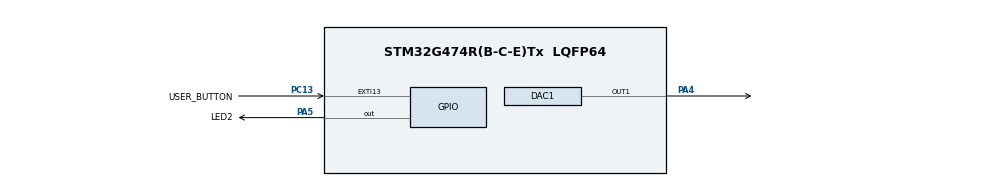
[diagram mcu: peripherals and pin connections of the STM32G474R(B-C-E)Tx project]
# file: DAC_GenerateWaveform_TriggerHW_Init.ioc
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DAC1.DAC_Trigger2_OUT1-DAC_OUT1=DAC_TRIGGER_NONE
DAC1.DAC_Trigger_OUT1-DAC_OUT1=DAC_TRIGGER_T6_TRGO
Dma.DAC1_CH1.0.Direction=DMA_MEMORY_TO_PERIPH
Dma.DAC1_CH1.0.EventEnable=DISABLE
Dma.DAC1_CH1.0.Instance=DMA1_Channel3
Dma.DAC1_CH1.0.MemDataAlignment=DMA_MDATAALIGN_HALFWORD
Dma.DAC1_CH1.0.MemInc=DMA_MINC_ENABLE
Dma.DAC1_CH1.0.Mode=DMA_CIRCULAR
Dma.DAC1_CH1.0.PeriphDataAlignment=DMA_PDATAALIGN_WORD
Dma.DAC1_CH1.0.PeriphInc=DMA_PINC_DISABLE
Dma.DAC1_CH1.0.Polarity=HAL_DMAMUX_REQUEST_GEN_RISING
Dma.DAC1_CH1.0.Priority=DMA_PRIORITY_HIGH
Dma.DAC1_CH1.0.RequestNumber=1
Dma.DAC1_CH1.0.SignalID=HAL_DMAMUX1_REQUEST_GEN_EXTI13
Dma.DAC1_CH1.0.SyncEnable=DISABLE
Dma.DAC1_CH1.0.SyncPolarity=HAL_DMAMUX_SYNC_NO_EVENT
Dma.DAC1_CH1.0.SyncRequestNumber=1
Dma.DAC1_CH1.0.SyncSignalID=HAL_DMAMUX1_SYNC_EXTI13
Dma.Request0=DAC1_CH1
Mcu.Family=STM32G4
Mcu.Name=STM32G474R(B-C-E)Tx
Mcu.Package=LQFP64
NVIC.DMA1_Channel3_IRQn=true\:0\:0\:false\:false\:true\:false\:true
NVIC.EXTI15_10_IRQn=true\:0\:0\:false\:false\:true\:true\:true
NVIC.PriorityGroup=NVIC_PRIORITYGROUP_4
NVIC.TIM6_DAC_IRQn=true\:0\:0\:false\:false\:true\:true\:true
PA4.Signal=COMP_DAC11_group
PA5.GPIO_Label=LED2
PA5.Signal=GPIO_Output
PC13.GPIO_Label=USER_BUTTON
PC13.GPIO_ModeDefaultEXTI=GPIO_MODE_IT_FALLING
PC13.Signal=GPXTI13
ProjectManager.HeapSize=0x200
ProjectManager.StackSize=0x400
ProjectManager.TargetToolchain=EWARM V8
RCC.ADC12Freq_Value=150000000
RCC.ADC345Freq_Value=150000000
RCC.AHBFreq_Value=150000000
RCC.APB1Freq_Value=150000000
RCC.APB1TimFreq_Value=150000000
RCC.APB2Freq_Value=150000000
RCC.APB2TimFreq_Value=150000000
RCC.CortexFreq_Value=150000000
RCC.EXTERNAL_CLOCK_VALUE=12288000
RCC.HCLKFreq_Value=150000000
RCC.HSE_VALUE=24000000
RCC.HSI48_VALUE=16000000
RCC.HSI_VALUE=16000000
RCC.LSE_VALUE=32768
RCC.PLLM=RCC_PLLM_DIV4
RCC.PLLN=75
RCC.SYSCLKFreq_VALUE=150000000
RCC.SYSCLKSource=RCC_SYSCLKSOURCE_PLLCLK
RCC.USBFreq_Value=150000000
RCC.VCOOutputFreq_Value=300000000
SH.COMP_DAC11_group.0=DAC1_OUT1,DAC_OUT1
TIM6.AutoReloadPreload=TIM_AUTORELOAD_PRELOAD_DISABLE
TIM6.CounterMode=TIM_COUNTERMODE_UP
TIM6.Period=(timer_reload - 1)
TIM6.Prescaler=(timer_prescaler - 1)
TIM6.TIM_MasterOutputTrigger=TIM_TRGO_UPDATE
VP_SYS_VS_DBSignals.Mode=DisableDeadBatterySignals
VP_TIM6_VS_ClockSourceINT.Mode=Enable_Timer
board=NUCLEO-G474RE

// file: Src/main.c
/* USER CODE BEGIN Header */
/**
  ******************************************************************************
  * @file    Examples_LL/DAC/DAC_GenerateWaveform_TriggerHW_Init/Src/main.c
  * @author  MCD Application Team
  * @brief   This example describes how to use the DAC peripheral to generate
  *          a voltage waveform from digital data stream transferred by DMA.
  *          This example is based on the STM32G4xx DAC LL API;
  *          Peripheral initialization done using LL initialization function.
  ******************************************************************************
  * @attention
  *
  * <h2><center>&copy; Copyright (c) 2019 STMicroelectronics.
  * All rights reserved.</center></h2>
  *
  * This software component is licensed by ST under BSD 3-Clause license,
  * the "License"; You may not use this file except in compliance with the
  * License. You may obtain a copy of the License at:
  *                        opensource.org/licenses/BSD-3-Clause
  *
  ******************************************************************************
  */
/* USER CODE END Header */
#include "main.h"

/* USER CODE BEGIN PD */

/* Definitions of environment analog values */
  /* Value of analog reference voltage (Vref+), connected to analog voltage   */
  /* supply Vdda (unit: mV).                                                  */
  #define VDDA_APPLI                       ((uint32_t)3300)

/* Definitions of data related to this example */
/* Full-scale digital value with a resolution of 12 bits (voltage range     */
/* determined by analog voltage references Vref+ and Vref-,                 */
/* refer to reference manual).                                              */
#define DIGITAL_SCALE_12BITS             (__LL_DAC_DIGITAL_SCALE(LL_DAC_RESOLUTION_12B))

/* Definitions of waveform generation values */
/* Waveform generation: parameters of waveform */
/* Waveform amplitude (unit: mV) */
#define WAVEFORM_AMPLITUDE          (VDDA_APPLI)
/* Waveform amplitude (unit: Hz) */
#define WAVEFORM_FREQUENCY          ((uint32_t)1000)
/* Size of array containing DAC waveform samples */
#define WAVEFORM_SAMPLES_SIZE       (sizeof (WaveformSine_12bits_32samples) / sizeof (uint16_t))

/* Waveform generation: parameters of timer (used as DAC trigger) */
/* Timer frequency (unit: Hz). With a timer 16 bits and time base           */
/* freq min 1Hz, range is min=1Hz, max=32kHz.                               */
#define WAVEFORM_TIMER_FREQUENCY                (WAVEFORM_FREQUENCY * WAVEFORM_SAMPLES_SIZE)
/* Timer minimum frequency (unit: Hz), used to calculate frequency range.   */
/* With a timer 16 bits, maximum frequency will be 32000 times this value.  */
#define WAVEFORM_TIMER_FREQUENCY_RANGE_MIN      ((uint32_t)    1)
/* Timer prescaler maximum value (0xFFFF for a timer 16 bits) */
#define WAVEFORM_TIMER_PRESCALER_MAX_VALUE      ((uint32_t)0xFFFF-1)

/**
  * @brief Toggle periods for various blinking modes
  */
#define LED_BLINK_FAST  200
#define LED_BLINK_SLOW  500
#define LED_BLINK_ERROR 1000

/* USER CODE END PD */

/* USER CODE BEGIN PM */

/**
  * @brief  Computation of a data from maximum value on digital scale 12 bits
  *         (corresponding to voltage Vdda)
  *         to a value on the new scale
  *         (corresponding to voltage defined by WAVEFORM_AMPLITUDE).
  * @param  __DATA_12BITS__: Digital value on scale 12 bits
  * @retval None
  */
#define __WAVEFORM_AMPLITUDE_SCALING(__DATA_12BITS__)                                     \
  (__DATA_12BITS__                                                                        \
   * __LL_DAC_CALC_VOLTAGE_TO_DATA(VDDA_APPLI, WAVEFORM_AMPLITUDE, LL_DAC_RESOLUTION_12B) \
   / __LL_DAC_DIGITAL_SCALE(LL_DAC_RESOLUTION_12B)                                        \
  )

/* USER CODE END PM */

/* USER CODE BEGIN PV */

__IO uint8_t ubButtonPress = 0;

uint32_t timer_prescaler = 0;                   /* Time base prescaler to have timebase aligned on minimum frequency possible */
uint32_t timer_reload = 0;                      /* Timer reload value in function of timer prescaler to achieve time base period */

const uint16_t WaveformSine_12bits_32samples[] =
{
__WAVEFORM_AMPLITUDE_SCALING(2048),
__WAVEFORM_AMPLITUDE_SCALING(2447),
__WAVEFORM_AMPLITUDE_SCALING(2831),
__WAVEFORM_AMPLITUDE_SCALING(3185),
__WAVEFORM_AMPLITUDE_SCALING(3495),
__WAVEFORM_AMPLITUDE_SCALING(3750),
__WAVEFORM_AMPLITUDE_SCALING(3939),
__WAVEFORM_AMPLITUDE_SCALING(4056),
__WAVEFORM_AMPLITUDE_SCALING(4095),
__WAVEFORM_AMPLITUDE_SCALING(4056),
__WAVEFORM_AMPLITUDE_SCALING(3939),
__WAVEFORM_AMPLITUDE_SCALING(3750),
__WAVEFORM_AMPLITUDE_SCALING(3495),
__WAVEFORM_AMPLITUDE_SCALING(3185),
__WAVEFORM_AMPLITUDE_SCALING(2831),
__WAVEFORM_AMPLITUDE_SCALING(2447),
__WAVEFORM_AMPLITUDE_SCALING(2048),
__WAVEFORM_AMPLITUDE_SCALING(1649),
__WAVEFORM_AMPLITUDE_SCALING(1265),
__WAVEFORM_AMPLITUDE_SCALING(911),
__WAVEFORM_AMPLITUDE_SCALING(601),
__WAVEFORM_AMPLITUDE_SCALING(346),
__WAVEFORM_AMPLITUDE_SCALING(157),
__WAVEFORM_AMPLITUDE_SCALING(40),
__WAVEFORM_AMPLITUDE_SCALING(0),
__WAVEFORM_AMPLITUDE_SCALING(40),
__WAVEFORM_AMPLITUDE_SCALING(157),
__WAVEFORM_AMPLITUDE_SCALING(346),
__WAVEFORM_AMPLITUDE_SCALING(601),
__WAVEFORM_AMPLITUDE_SCALING(911),
__WAVEFORM_AMPLITUDE_SCALING(1265),
__WAVEFORM_AMPLITUDE_SCALING(1649)
};

/* USER CODE END PV */

void SystemClock_Config(void);
static void MX_GPIO_Init(void);
static void MX_DMA_Init(void);
static void MX_DAC1_Init(void);
static void MX_TIM6_Init(void);
/* USER CODE BEGIN PFP */

void Activate_DAC(void);
void LED_On(void);
void LED_Off(void);
void LED_Blinking(uint32_t Period);
void WaitForUserButtonPress(void);
void TIM_PrescalerReloadCalculation(void);

/* USER CODE END PFP */

int main(void)
{

  /* MCU Configuration--------------------------------------------------------*/

  /* Reset of all peripherals, Initializes the Flash interface and the Systick. */

  LL_APB2_GRP1_EnableClock(LL_APB2_GRP1_PERIPH_SYSCFG);
  LL_APB1_GRP1_EnableClock(LL_APB1_GRP1_PERIPH_PWR);

  NVIC_SetPriorityGrouping(NVIC_PRIORITYGROUP_4);

  /* System interrupt init*/

  /** Disable the internal Pull-Up in Dead Battery pins of UCPD peripheral
  */
  LL_PWR_DisableUCPDDeadBattery();

  /* Configure the system clock */
  SystemClock_Config();

  /* USER CODE BEGIN SysInit */
  TIM_PrescalerReloadCalculation();

  /* USER CODE END SysInit */

  /* Initialize all configured peripherals */
  MX_GPIO_Init();
  MX_DMA_Init();
  MX_DAC1_Init();
  MX_TIM6_Init();
  /* USER CODE BEGIN 2 */

  /* Wait for User push-button press */
  WaitForUserButtonPress();

  /* Turn-off LED4 */
  LED_Off();

  /* Set DMA transfer addresses of source and destination */
  LL_DMA_ConfigAddresses(DMA1,
                         LL_DMA_CHANNEL_3,
                         (uint32_t)&WaveformSine_12bits_32samples,
                         LL_DAC_DMA_GetRegAddr(DAC1, LL_DAC_CHANNEL_1, LL_DAC_DMA_REG_DATA_12BITS_RIGHT_ALIGNED),
                         LL_DMA_DIRECTION_MEMORY_TO_PERIPH);

  /* Set DMA transfer size */
  LL_DMA_SetDataLength(DMA1,
                       LL_DMA_CHANNEL_3,
                       WAVEFORM_SAMPLES_SIZE);

  /* Enable DMA transfer interruption: transfer error */
  LL_DMA_EnableIT_TE(DMA1,
                     LL_DMA_CHANNEL_3);

  /* Note: In this example, the only DMA interruption activated is            */
  /*       transfer error.                                                     */
  /*       If needed, DMA interruptions of half of transfer                   */
  /*       and transfer complete can be activated.                            */
  /*       Refer to DMA examples.                                             */

  /* Activation of DMA */
  /* Enable the DMA transfer */
  LL_DMA_EnableChannel(DMA1,
                       LL_DMA_CHANNEL_3);

  /* Set DAC mode sample-and-hold timings */
  // LL_DAC_SetSampleAndHoldSampleTime (DAC1, LL_DAC_CHANNEL_1, 0x3FF);
  // LL_DAC_SetSampleAndHoldHoldTime   (DAC1, LL_DAC_CHANNEL_1, 0x3FF);
  // LL_DAC_SetSampleAndHoldRefreshTime(DAC1, LL_DAC_CHANNEL_1, 0xFF);

  /* Set the mode for the selected DAC channel */
  // LL_DAC_SetMode(DAC1, LL_DAC_CHANNEL_1, LL_DAC_MODE_NORMAL_OPERATION);

  /* Enable DAC channel DMA request */
  LL_DAC_EnableDMAReq(DAC1, LL_DAC_CHANNEL_1);

  /* Enable interruption DAC channel1 under-run */
  LL_DAC_EnableIT_DMAUDR1(DAC1);

  /* Activation of Timer */
  /* Enable counter */
  LL_TIM_EnableCounter(TIM6);

  /* Activation of DAC channel */
  Activate_DAC();

  /* Turn-on LED4 */
  LED_On();

  /* USER CODE END 2 */

  /* Infinite loop */
  while (1)
  {

  }
}

void SystemClock_Config(void)
{
  LL_FLASH_SetLatency(LL_FLASH_LATENCY_4);
  while(LL_FLASH_GetLatency() != LL_FLASH_LATENCY_4)
  {
  }
  LL_PWR_SetRegulVoltageScaling(LL_PWR_REGU_VOLTAGE_SCALE1);
  LL_RCC_HSI_Enable();
   /* Wait till HSI is ready */
  while(LL_RCC_HSI_IsReady() != 1)
  {
  }

  LL_RCC_HSI_SetCalibTrimming(64);
  LL_RCC_PLL_ConfigDomain_SYS(LL_RCC_PLLSOURCE_HSI, LL_RCC_PLLM_DIV_4, 75, LL_RCC_PLLR_DIV_2);
  LL_RCC_PLL_EnableDomain_SYS();
  LL_RCC_PLL_Enable();
   /* Wait till PLL is ready */
  while(LL_RCC_PLL_IsReady() != 1)
  {
  }

  LL_RCC_SetSysClkSource(LL_RCC_SYS_CLKSOURCE_PLL);
  LL_RCC_SetAHBPrescaler(LL_RCC_SYSCLK_DIV_2);
   /* Wait till System clock is ready */
  while(LL_RCC_GetSysClkSource() != LL_RCC_SYS_CLKSOURCE_STATUS_PLL)
  {
  }

  /* Insure 1�s transition state at intermediate medium speed clock based on DWT */
  CoreDebug->DEMCR |= CoreDebug_DEMCR_TRCENA_Msk;
  DWT->CTRL |= DWT_CTRL_CYCCNTENA_Msk;
  DWT->CYCCNT = 0;
  while(DWT->CYCCNT < 100);
  /* Set AHB prescaler*/
  LL_RCC_SetAHBPrescaler(LL_RCC_SYSCLK_DIV_1);
  LL_RCC_SetAPB1Prescaler(LL_RCC_APB1_DIV_1);
  LL_RCC_SetAPB2Prescaler(LL_RCC_APB2_DIV_1);

  LL_Init1msTick(150000000);

  LL_SetSystemCoreClock(150000000);
}

static void MX_DAC1_Init(void)
{

  LL_DAC_InitTypeDef DAC_InitStruct = {0};

  LL_GPIO_InitTypeDef GPIO_InitStruct = {0};

  /* Peripheral clock enable */
  LL_AHB2_GRP1_EnableClock(LL_AHB2_GRP1_PERIPH_DAC1);

  LL_AHB2_GRP1_EnableClock(LL_AHB2_GRP1_PERIPH_GPIOA);
  /**DAC1 GPIO Configuration
  PA4   ------> DAC1_OUT1
  */
  GPIO_InitStruct.Pin = LL_GPIO_PIN_4;
  GPIO_InitStruct.Mode = LL_GPIO_MODE_ANALOG;
  GPIO_InitStruct.Pull = LL_GPIO_PULL_NO;
  LL_GPIO_Init(GPIOA, &GPIO_InitStruct);

  /* DAC1 DMA Init */

  /* DAC1_CH1 Init */
  LL_DMA_SetPeriphRequest(DMA1, LL_DMA_CHANNEL_3, LL_DMAMUX_REQ_DAC1_CH1);

  LL_DMA_SetDataTransferDirection(DMA1, LL_DMA_CHANNEL_3, LL_DMA_DIRECTION_MEMORY_TO_PERIPH);

  LL_DMA_SetChannelPriorityLevel(DMA1, LL_DMA_CHANNEL_3, LL_DMA_PRIORITY_HIGH);

  LL_DMA_SetMode(DMA1, LL_DMA_CHANNEL_3, LL_DMA_MODE_CIRCULAR);

  LL_DMA_SetPeriphIncMode(DMA1, LL_DMA_CHANNEL_3, LL_DMA_PERIPH_NOINCREMENT);

  LL_DMA_SetMemoryIncMode(DMA1, LL_DMA_CHANNEL_3, LL_DMA_MEMORY_INCREMENT);

  LL_DMA_SetPeriphSize(DMA1, LL_DMA_CHANNEL_3, LL_DMA_PDATAALIGN_WORD);

  LL_DMA_SetMemorySize(DMA1, LL_DMA_CHANNEL_3, LL_DMA_MDATAALIGN_HALFWORD);

  /* DAC1 interrupt Init */
  NVIC_SetPriority(TIM6_DAC_IRQn, NVIC_EncodePriority(NVIC_GetPriorityGrouping(),0, 0));
  NVIC_EnableIRQ(TIM6_DAC_IRQn);

  /** DAC channel OUT1 config
  */
  LL_DAC_SetSignedFormat(DAC1, LL_DAC_CHANNEL_1, LL_DAC_SIGNED_FORMAT_DISABLE);
  DAC_InitStruct.TriggerSource = LL_DAC_TRIG_EXT_TIM6_TRGO;
  DAC_InitStruct.TriggerSource2 = LL_DAC_TRIG_SOFTWARE;
  DAC_InitStruct.WaveAutoGeneration = LL_DAC_WAVE_AUTO_GENERATION_NONE;
  DAC_InitStruct.OutputBuffer = LL_DAC_OUTPUT_BUFFER_ENABLE;
  DAC_InitStruct.OutputConnection = LL_DAC_OUTPUT_CONNECT_GPIO;
  DAC_InitStruct.OutputMode = LL_DAC_OUTPUT_MODE_NORMAL;
  LL_DAC_Init(DAC1, LL_DAC_CHANNEL_1, &DAC_InitStruct);
  LL_DAC_EnableTrigger(DAC1, LL_DAC_CHANNEL_1);
  LL_DAC_DisableDMADoubleDataMode(DAC1, LL_DAC_CHANNEL_1);

}

static void MX_TIM6_Init(void)
{

  LL_TIM_InitTypeDef TIM_InitStruct = {0};

  /* Peripheral clock enable */
  LL_APB1_GRP1_EnableClock(LL_APB1_GRP1_PERIPH_TIM6);

  /* TIM6 interrupt Init */
  NVIC_SetPriority(TIM6_DAC_IRQn, NVIC_EncodePriority(NVIC_GetPriorityGrouping(),0, 0));
  NVIC_EnableIRQ(TIM6_DAC_IRQn);

  TIM_InitStruct.Prescaler = (timer_prescaler - 1);
  TIM_InitStruct.CounterMode = LL_TIM_COUNTERMODE_UP;
  TIM_InitStruct.Autoreload = (timer_reload - 1);
  LL_TIM_Init(TIM6, &TIM_InitStruct);
  LL_TIM_DisableARRPreload(TIM6);
  LL_TIM_SetTriggerOutput(TIM6, LL_TIM_TRGO_UPDATE);
  LL_TIM_DisableMasterSlaveMode(TIM6);

}

static void MX_DMA_Init(void)
{

  /* Init with LL driver */
  /* DMA controller clock enable */
  LL_AHB1_GRP1_EnableClock(LL_AHB1_GRP1_PERIPH_DMAMUX1);
  LL_AHB1_GRP1_EnableClock(LL_AHB1_GRP1_PERIPH_DMA1);

  /* DMA interrupt init */
  /* DMA1_Channel3_IRQn interrupt configuration */
  NVIC_SetPriority(DMA1_Channel3_IRQn, NVIC_EncodePriority(NVIC_GetPriorityGrouping(),0, 0));
  NVIC_EnableIRQ(DMA1_Channel3_IRQn);

}

static void MX_GPIO_Init(void)
{
  LL_EXTI_InitTypeDef EXTI_InitStruct = {0};
  LL_GPIO_InitTypeDef GPIO_InitStruct = {0};

  /* GPIO Ports Clock Enable */
  LL_AHB2_GRP1_EnableClock(LL_AHB2_GRP1_PERIPH_GPIOC);
  LL_AHB2_GRP1_EnableClock(LL_AHB2_GRP1_PERIPH_GPIOA);

  /**/
  LL_GPIO_ResetOutputPin(LED2_GPIO_Port, LED2_Pin);

  /**/
  LL_SYSCFG_SetEXTISource(LL_SYSCFG_EXTI_PORTC, LL_SYSCFG_EXTI_LINE13);

  /**/
  EXTI_InitStruct.Line_0_31 = LL_EXTI_LINE_13;
  EXTI_InitStruct.LineCommand = ENABLE;
  EXTI_InitStruct.Mode = LL_EXTI_MODE_IT;
  EXTI_InitStruct.Trigger = LL_EXTI_TRIGGER_FALLING;
  LL_EXTI_Init(&EXTI_InitStruct);

  /**/
  LL_GPIO_SetPinPull(USER_BUTTON_GPIO_Port, USER_BUTTON_Pin, LL_GPIO_PULL_NO);

  /**/
  LL_GPIO_SetPinMode(USER_BUTTON_GPIO_Port, USER_BUTTON_Pin, LL_GPIO_MODE_INPUT);

  /**/
  GPIO_InitStruct.Pin = LED2_Pin;
  GPIO_InitStruct.Mode = LL_GPIO_MODE_OUTPUT;
  GPIO_InitStruct.Speed = LL_GPIO_SPEED_FREQ_LOW;
  GPIO_InitStruct.OutputType = LL_GPIO_OUTPUT_PUSHPULL;
  GPIO_InitStruct.Pull = LL_GPIO_PULL_NO;
  LL_GPIO_Init(LED2_GPIO_Port, &GPIO_InitStruct);

  /* EXTI interrupt init*/
  NVIC_SetPriority(EXTI15_10_IRQn, NVIC_EncodePriority(NVIC_GetPriorityGrouping(),0, 0));
  NVIC_EnableIRQ(EXTI15_10_IRQn);

}

/* USER CODE BEGIN 4 */

/**
  * @brief  Perform DAC activation procedure to make it ready to generate
  *         a voltage (DAC instance: DAC1).
  * @note   Operations:
  *         - Enable DAC instance channel
  *         - Wait for DAC instance channel startup time
  * @param  None
  * @retval None
  */
void Activate_DAC(void)
{
  __IO uint32_t wait_loop_index = 0;

  /* Enable DAC channel */
  LL_DAC_Enable(DAC1, LL_DAC_CHANNEL_1);

  /* Delay for DAC channel voltage settling time from DAC channel startup.    */
  /* Compute number of CPU cycles to wait for, from delay in us.              */
  /* Note: Variable divided by 2 to compensate partially                      */
  /*       CPU processing cycles (depends on compilation optimization).       */
  /* Note: If system core clock frequency is below 200kHz, wait time          */
  /*       is only a few CPU processing cycles.                               */
  wait_loop_index = ((LL_DAC_DELAY_STARTUP_VOLTAGE_SETTLING_US * (SystemCoreClock / (100000 * 2))) / 10);
  while(wait_loop_index != 0)
  {
    wait_loop_index--;
  }

  /* Enable DAC channel trigger */
  /* Note: DAC channel conversion can start from trigger enable:              */
  /*       - if DAC channel trigger source is set to SW:                      */
  /*         DAC channel conversion will start after trig order               */
  /*         using function "LL_DAC_TrigSWConversion()".                      */
  /*       - if DAC channel trigger source is set to external trigger         */
  /*         (timer, ...):                                                    */
  /*         DAC channel conversion can start immediately                     */
  /*         (after next trig order from external trigger)                    */
  LL_DAC_EnableTrigger(DAC1, LL_DAC_CHANNEL_1);
}

/**
  * @brief  Function to manage IRQ Handler
  * @param  None
  * @retval None
  */
void UserButton_Callback(void)
{
  /* On the first press on user button, update only user button variable      */
  /* to manage waiting function.                                              */
  if(ubButtonPress == 0)
  {
    /* Update User push-button variable : to be checked in waiting loop in main program */
    ubButtonPress = 1;
  }
}

/**
  * @brief  DMA transfer error callback
  * @note   This function is executed when the transfer error interrupt
  *         is generated during DMA transfer
  * @retval None
  */
void DacDmaTransferError_Callback()
{
  /* Error detected during DMA transfer */
  LED_Blinking(LED_BLINK_ERROR);
}

/**
  * @brief  DAC under-run interruption callback
  * @note   This function is executed when DAC channel under-run error occurs.
  * @retval None
  */
void DacUnderrunError_Callback(void)
{
  /* Note: Disable DAC interruption that caused this error before entering in */
  /*       infinite loop below.                                               */

  /* Disable interruption DAC channel1 under-run */
  LL_DAC_DisableIT_DMAUDR1(DAC1);

  /* Error from ADC */
  LED_Blinking(LED_BLINK_ERROR);
}

/**
  * @brief  Turn-on LED4.
  * @param  None
  * @retval None
  */
void LED_On(void)
{
  /* Turn LED4 on */
  LL_GPIO_SetOutputPin(LED2_GPIO_Port, LED2_Pin);
}

/**
  * @brief  Turn-off LED4.
  * @param  None
  * @retval None
  */
void LED_Off(void)
{
  /* Turn LED4 off */
  LL_GPIO_ResetOutputPin(LED2_GPIO_Port, LED2_Pin);
}

/**
  * @brief  Set LED4 to Blinking mode for an infinite loop (toggle period based on value provided as input parameter).
  * @param  Period : Period of time (in ms) between each toggling of LED
  *   This parameter can be user defined values. Pre-defined values used in that example are :
  *     @arg LED_BLINK_FAST : Fast Blinking
  *     @arg LED_BLINK_SLOW : Slow Blinking
  *     @arg LED_BLINK_ERROR : Error specific Blinking
  * @retval None
  */
void LED_Blinking(uint32_t Period)
{
  /* Turn LED4 on */
  LL_GPIO_SetOutputPin(LED2_GPIO_Port, LED2_Pin);

  /* Toggle IO in an infinite loop */
  while (1)
  {
    LL_GPIO_TogglePin(LED2_GPIO_Port, LED2_Pin);
    LL_mDelay(Period);
  }
}

/**
  * @brief  Wait for User push-button press to start transfer.
  * @param  None
  * @retval None
  */
void WaitForUserButtonPress(void)
{
  while (ubButtonPress == 0)
  {
    LL_GPIO_TogglePin(LED2_GPIO_Port, LED2_Pin);
    LL_mDelay(LED_BLINK_FAST);
  }
  ubButtonPress = 0;
}

/**
  * @brief  Calculate prescaler and reload values for timer.
  * @param  None
  * @retval None
  */
void TIM_PrescalerReloadCalculation(void)
{
  uint32_t timer_clock_frequency = 0;             /* Timer clock frequency */

  /* Configuration of timer as time base:                                     */
  /* Caution: Computation of frequency is done for a timer instance on APB1   */
  /*          (clocked by PCLK1)                                              */
  /* Timer frequency is configured from the following constants:              */
  /* - WAVEFORM_TIMER_FREQUENCY: timer frequency (unit: Hz).                  */
  /* - WAVEFORM_TIMER_FREQUENCY_RANGE_MIN: timer minimum frequency possible   */
  /*   (unit: Hz).                                                            */
  /* Note: Refer to comments at these literals definition for more details.   */

  /* Retrieve timer clock source frequency */
  /* If APB1 prescaler is different of 1, timers have a factor x2 on their    */
  /* clock source.                                                            */
  if (LL_RCC_GetAPB1Prescaler() == LL_RCC_APB1_DIV_1)
  {
    timer_clock_frequency = __LL_RCC_CALC_PCLK1_FREQ(SystemCoreClock, LL_RCC_GetAPB1Prescaler());
  }
  else
  {
    timer_clock_frequency = (__LL_RCC_CALC_PCLK1_FREQ(SystemCoreClock, LL_RCC_GetAPB1Prescaler()) * 2);
  }

  /* Timer prescaler calculation */
  /* (computation for timer 16 bits, additional + 1 to round the prescaler up) */
  timer_prescaler = ((timer_clock_frequency / (WAVEFORM_TIMER_PRESCALER_MAX_VALUE * WAVEFORM_TIMER_FREQUENCY_RANGE_MIN)) +1);
  /* Timer reload calculation */
  timer_reload = (timer_clock_frequency / (timer_prescaler * WAVEFORM_TIMER_FREQUENCY));
}

/* USER CODE END 4 */

void Error_Handler(void)
{
}

/************************ (C) COPYRIGHT STMicroelectronics *****END OF FILE****/
